# PY32F032xx register map
Vendor: Puya; Series: PY32F0; File version: 1.0.0
CPU: CM0+ r0p1, little endian, no MPU, no FPU, 4 interrupt priority bits
Registers are 32-bit, read-write, reset 0x0 unless marked. A register's access mark holds for its fields unless they carry their own. Offsets are from the block's base; [hi:lo] are bit positions.

## I2C1 — Inter integrated circuit
Base 0x40005400
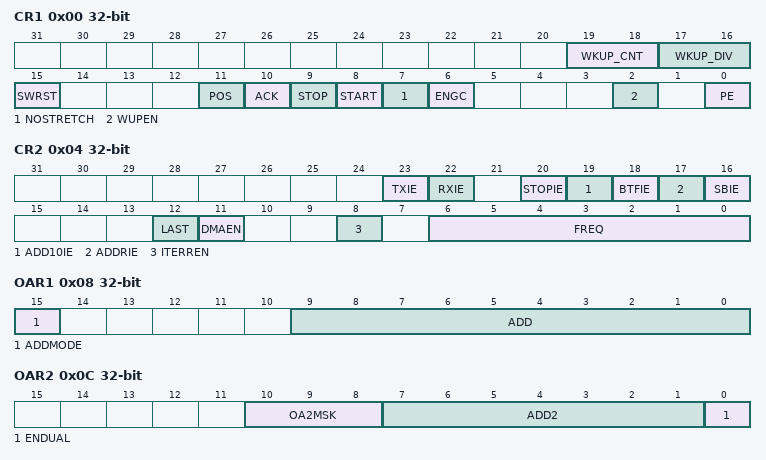
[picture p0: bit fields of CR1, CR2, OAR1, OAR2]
0x00 CR1 — Control register 1
  [19:18] WKUP_CNT — Timeout count number
    1=0; 2=1
  [17:16] WKUP_DIV — PCLK division
    1=0; 2=1
  [15] SWRST — Software reset
  [11] POS — Acknowledge(for data reception)
  [10] ACK — Acknowledge enable
  [9] STOP — Stop generation
  [8] START — Start generation
  [7] NOSTRETCH — Clock stretching disable (Slave mode)
  [6] ENGC — General call enable
  [2] WUPEN — Wakeup from Stop mode enable
  [0] PE — Peripheral enable
0x04 CR2 — Control register 2
  [23] TXIE — Data register empty (transmitters) interrupt enable
  [22] RXIE — Data register not empty (receivers) interrupt enable
  [20] STOPIE — Stop detection (slave mode) interrupt enable
  [19] ADD10IE — 10-bit header sent (Master mode) interrupt enable
  [18] BTFIE — Byte transfer finished interrupt enable
  [17] ADDRIE — Address sent (master mode)/matched (slave mode) interrupt enable
  [16] SBIE — Start bit (Master mode) interrupt enable
  [12] LAST — DMA last transfer
  [11] DMAEN — DMA requests enable
  [8] ITERREN — Error interrupt enable
  [6:0] FREQ — Peripheral clock frequency
0x08 OAR1 — Own address register 1
  [15] ADDMODE — Addressing mode (slave mode)
  [9:0] ADD — Interface address
0x0C OAR2
  [10:8] OA2MSK — Own Address 2 masks
    1=0; 2=1; 4=2
  [7:1] ADD2 — Interface address
  [0] ENDUAL — Dual addressing mode enable
0x10 DR — Data register
  [7:0] DR — 8-bit data register
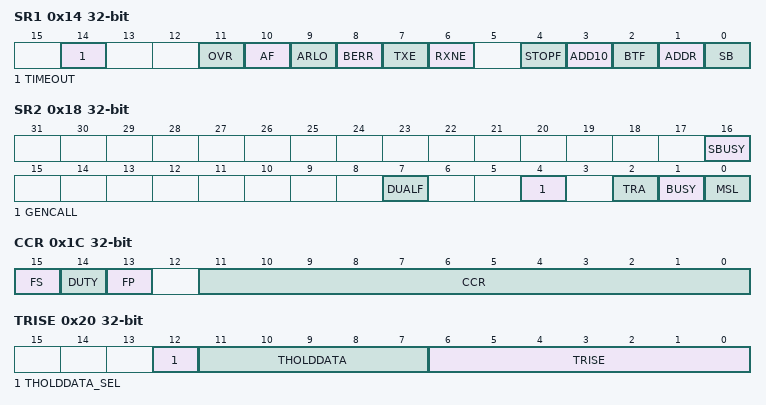
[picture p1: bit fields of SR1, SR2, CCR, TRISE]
0x14 SR1 — Status register 1
  [14] TIMEOUT — Timeout or Tlow error
  [11] OVR — Overrun/Underrun
  [10] AF — Acknowledge failure
  [9] ARLO — Arbitration lost (master mode)
  [8] BERR — Bus error
  [7] TXE ro — Data register empty (transmitters)
  [6] RXNE ro — Data register not empty (receivers)
  [4] STOPF ro — Stop detection (slave mode)
  [3] ADD10 ro — 10-bit header sent (Master mode)
  [2] BTF ro — Byte transfer finished
  [1] ADDR ro — Address sent (master mode)/matched (slave mode)
  [0] SB ro — Start bit (Master mode)
0x18 SR2 — Status register 2
  [16] SBUSY ro — Slave busy
  [7] DUALF ro — Dual flag (Slave mode)
  [4] GENCALL ro — General call address (Slave mode)
  [2] TRA ro — Transmitter/receiver
  [1] BUSY ro — Bus busy
  [0] MSL ro — Master/slave
0x1C CCR — Clock control register
  [15] FS — I2C master mode selection
  [14] DUTY — Fm mode duty cycle
  [13] FP — I2C master mode selection
  [11:0] CCR — Clock control register in Fm/Sm mode (Master mode)
0x20 TRISE
  [12] THOLDDATA_SEL — Data hold time select
  [11:7] THOLDDATA — Data hold time
    1=0; 2=1; 4=2; 8=3; 16=4
  [6:0] TRISE — Maximum rise time in Fm+/Fm/Sm mode (Master mode)
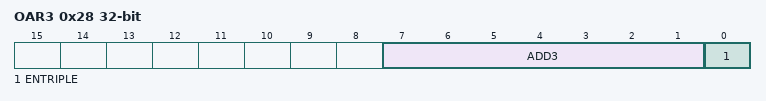
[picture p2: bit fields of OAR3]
0x28 OAR3
  [7:1] ADD3 — Interface address
  [0] ENTRIPLE — Triple addressing mode enable

## IWDG — Independent watchdog
Base 0x40003000
0x00 KR — Key register (IWDG_KR)
  [15:0] KEY — IWDG KEY
0x04 PR — Prescaler register (IWDG_PR)
  [2:0] PR — IWDG preload
    1=0; 2=1; 4=2
0x08 RLR — Reload register (IWDG_RLR)
  [11:0] RL — IWDG reload
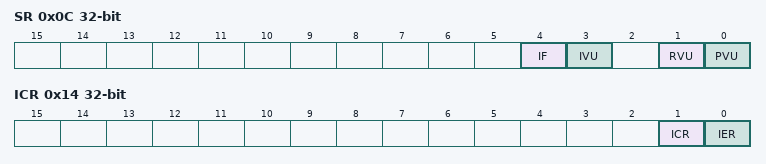
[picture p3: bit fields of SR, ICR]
0x0C SR — Status register (IWDG_SR)
  [4] IF ro — Watchdog interrupt status
  [3] IVU ro — Watchdog Interrupt value update
  [1] RVU ro — Watchdog counter reload value update
  [0] PVU ro — Watchdog prescaler value update
0x10 ICNTR
  [11:0] ICNTR — Watchdog prescaler value update
0x14 ICR
  [1] ICR — Watchdog interrupt status clear
  [0] IER — Watchdog Interrupt enable

## LPTIM — Low power timer
Base 0x40007C00
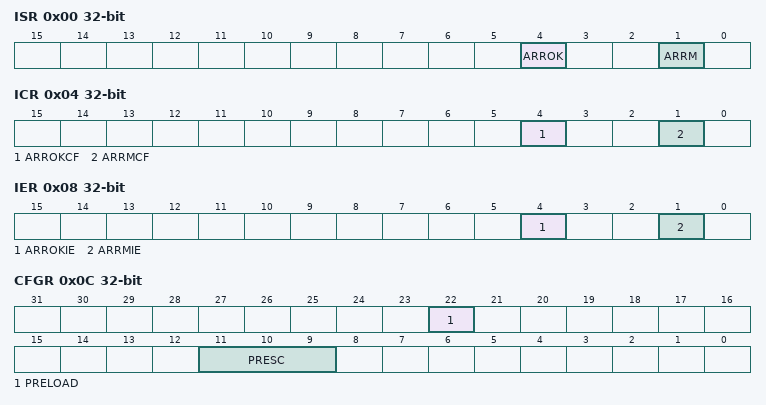
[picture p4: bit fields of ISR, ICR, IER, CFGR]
0x00 ISR — Interrupt and Status Register
  [4] ARROK ro — Autoreload register update OK
  [1] ARRM ro — Autoreload match
0x04 ICR — Interrupt Clear Register
  [4] ARROKCF — Autoreload register update OK clear flag
  [1] ARRMCF — Autoreload match clear flag
0x08 IER — Interrupt Enable Register
  [4] ARROKIE — Autoreload register update OK Interrupt Enable
  [1] ARRMIE — Autoreload match Interrupt Enable
0x0C CFGR — Configuration Register
  [22] PRELOAD — Registers update mode
  [11:9] PRESC — Clock prescaler
    1=0; 2=1; 4=2
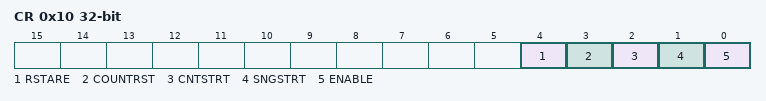
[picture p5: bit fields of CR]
0x10 CR — Control Register
  [4] RSTARE — Reset after read enable
  [3] COUNTRST — Counter reset
  [2] CNTSTRT — Timer start in Continuous mode
  [1] SNGSTRT — LPTIM start in Single mode
  [0] ENABLE — LPTIM enable
0x18 ARR — Autoreload Register
  [15:0] ARR — Auto reload value
0x1C CNT — Counter Register
  [15:0] CNT ro — Counter value
